# npcx4m8f register map
Registers are 8-bit, read-write, no defined reset value unless marked. A register's access mark holds for its fields unless they carry their own. Offsets are from the block's base; [hi:lo] are bit positions; {n}, {i} and the like mark numbered series.

## FIU — Flash Interface Unit
Base 0x40020000
0x00 FIU_CFG
  [7:0] FL_SIZE
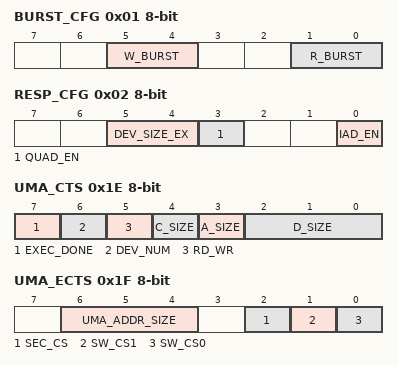
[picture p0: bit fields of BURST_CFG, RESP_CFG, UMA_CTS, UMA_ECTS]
0x01 BURST_CFG
  [5:4] W_BURST, [1:0] R_BURST
0x02 RESP_CFG
  [5:4] DEV_SIZE_EX, [3] QUAD_EN, [0] IAD_EN
0x14 SPI_FL_CFG
  [5:0] DEV_SIZE
0x16 UMA_CODE
{0x17+i} UMA_AB{i} (i=0..2)
{0x1A+i} UMA_DB{i} (i=0..3)
0x1E UMA_CTS
  [7] EXEC_DONE, [6] DEV_NUM, [5] RD_WR, [4] C_SIZE, [3] A_SIZE, [2:0] D_SIZE
0x1F UMA_ECTS
  [6:4] UMA_ADDR_SIZE, [2] SEC_CS, [1] SW_CS1, [0] SW_CS0
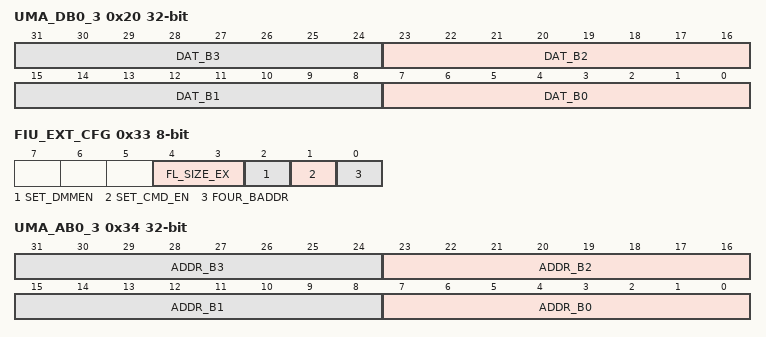
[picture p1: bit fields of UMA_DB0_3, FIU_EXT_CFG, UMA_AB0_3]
0x20 UMA_DB0_3 32-bit
  [8n+7:8n] DAT_B{n} (n=0..3)
0x30 UMA_RD_CMD
0x32 FIU_DMM_CYC
0x33 FIU_EXT_CFG
  [4:3] FL_SIZE_EX, [2] SET_DMMEN, [1] SET_CMD_EN, [0] FOUR_BADDR
0x34 UMA_AB0_3 32-bit
  [8n+7:8n] ADDR_B{n} (n=0..3)

## KBS — Keyboard Scan Module
Base 0x400A3000
0x04 KBSIN
0x05 KBSINPU
0x06 KBSOUT0 16-bit
0x08 KBSOUT1 16-bit
0x0A KBS_BUF_INDX
0x0B KBS_BUF_DATA
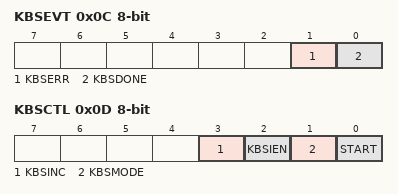
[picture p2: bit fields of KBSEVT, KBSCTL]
0x0C KBSEVT
  [1] KBSERR, [0] KBSDONE
0x0D KBSCTL
  [3] KBSINC, [2] KBSIEN, [1] KBSMODE, [0] START

## HFCG — High-Frequency Clock Generator
Base 0x400B5000
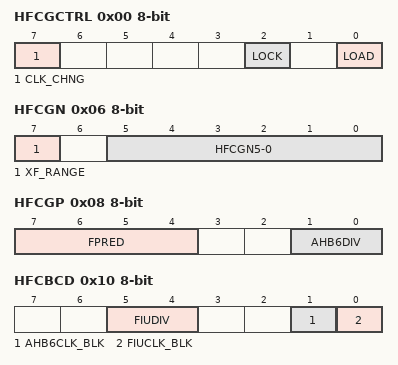
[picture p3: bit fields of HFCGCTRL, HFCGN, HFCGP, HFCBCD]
0x00 HFCGCTRL
  [7] CLK_CHNG, [2] LOCK, [0] LOAD
0x02 HFCGML
  [7:0] HFCGM7-0
0x04 HFCGMH
  [7:0] HFCGM15-8
0x06 HFCGN
  [7] XF_RANGE, [5:0] HFCGN5-0
0x08 HFCGP
  [7:4] FPRED, [1:0] AHB6DIV
0x0A HFCG_VER
  [3:0] HFCG_VER
0x10 HFCBCD
  [5:4] FIUDIV, [1] AHB6CLK_BLK, [0] FIUCLK_BLK
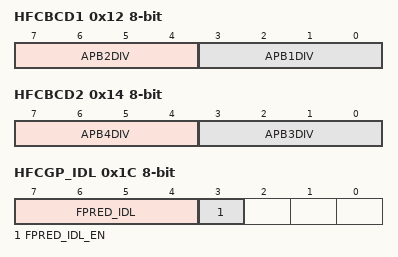
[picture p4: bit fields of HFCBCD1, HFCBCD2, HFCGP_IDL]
0x12 HFCBCD1
  [7:4] APB2DIV, [3:0] APB1DIV
0x14 HFCBCD2
  [7:4] APB4DIV, [3:0] APB3DIV
0x1C HFCGP_IDL
  [7:4] FPRED_IDL, [3] FPRED_IDL_EN

## LFCG — Low-Frequency Clock Generator
Base 0x400B5100
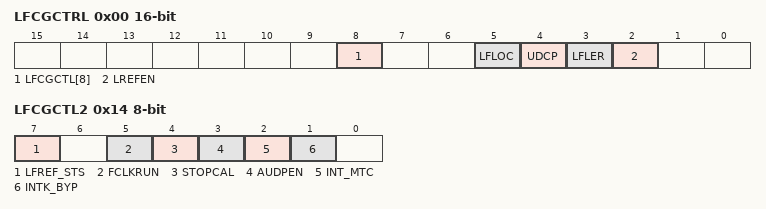
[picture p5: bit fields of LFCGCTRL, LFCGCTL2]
0x00 LFCGCTRL 16-bit
  [8] LFCGCTL[8], [5] LFLOC, [4] UDCP, [3] LFLER, [2] LREFEN
0x02 HFRDI 16-bit
  [11:0] HFRDI11-0
0x04 HFRDF 16-bit
  [15:0] HFRDF15-0
0x06 FRCDIV 16-bit
  [8:0] FRCDIV8-0
0x08 DIVMIN 16-bit
  [8:0] DIVMIN8-0
0x0A DIVMAX 16-bit
  [8:0] DIVMAX8-0
0x0E LFCG_VER
0x14 LFCGCTL2
  [7] LFREF_STS, [5] FCLKRUN, [4] STOPCAL, [3] AUDPEN, [2] INT_MTC, [1] INTK_BYP

## CR_UART0 — Core UART
Base 0x400E0000
Same registers: CR_UART1 0x400E2000, CR_UART2 0x400E4000, CR_UART3 0x400E6000
0x00 UTBUF
0x02 URBUF
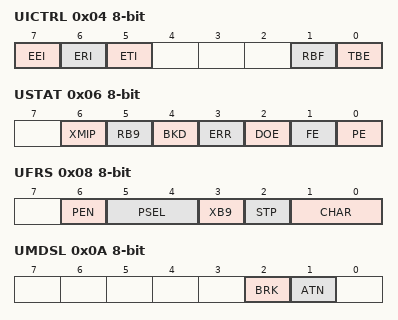
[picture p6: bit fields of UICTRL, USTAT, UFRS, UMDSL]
0x04 UICTRL
  [7] EEI, [6] ERI, [5] ETI, [1] RBF, [0] TBE
0x06 USTAT
  [6] XMIP, [5] RB9, [4] BKD, [3] ERR, [2] DOE, [1] FE, [0] PE
0x08 UFRS
  [6] PEN, [5:4] PSEL, [3] XB9, [2] STP, [1:0] CHAR
0x0A UMDSL
  [2] BRK, [1] ATN
0x0C UBAUD
  [7:0] UDIV7-0
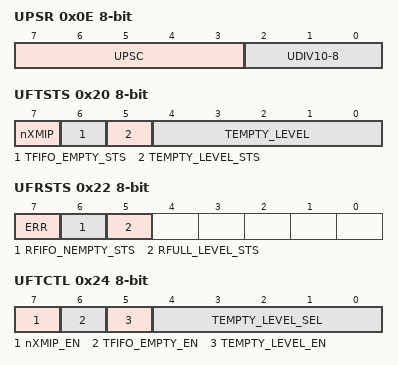
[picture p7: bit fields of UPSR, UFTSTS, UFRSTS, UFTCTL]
0x0E UPSR
  [7:3] UPSC, [2:0] UDIV10-8
0x20 UFTSTS
  [7] nXMIP, [6] TFIFO_EMPTY_STS, [5] TEMPTY_LEVEL_STS, [4:0] TEMPTY_LEVEL
0x22 UFRSTS
  [7] ERR, [6] RFIFO_NEMPTY_STS, [5] RFULL_LEVEL_STS
0x24 UFTCTL
  [7] nXMIP_EN, [6] TFIFO_EMPTY_EN, [5] TEMPTY_LEVEL_EN, [4:0] TEMPTY_LEVEL_SEL
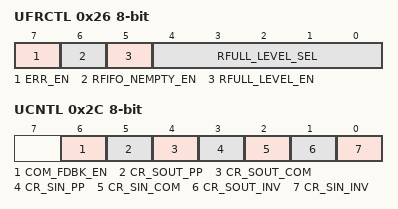
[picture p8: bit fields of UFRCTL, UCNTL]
0x26 UFRCTL
  [7] ERR_EN, [6] RFIFO_NEMPTY_EN, [5] RFULL_LEVEL_EN, [4:0] RFULL_LEVEL_SEL
0x2C UCNTL
  [6] COM_FDBK_EN, [5] CR_SOUT_PP, [4] CR_SOUT_COM, [3] CR_SIN_PP, [2] CR_SIN_COM, [1] CR_SOUT_INV, [0] CR_SIN_INV

## PECI — PECI Controller
Base 0x400D4000
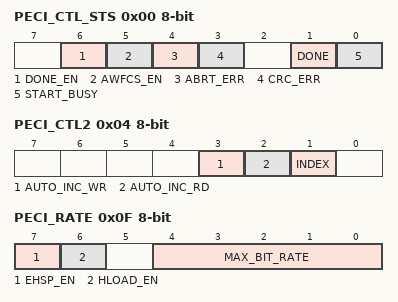
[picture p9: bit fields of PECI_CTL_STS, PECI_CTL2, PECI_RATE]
0x00 PECI_CTL_STS
  [6] DONE_EN, [5] AWFCS_EN, [4] ABRT_ERR, [3] CRC_ERR, [1] DONE, [0] START_BUSY
0x01 PECI_RD_LENGTH
0x02 PECI_ADDR
0x03 PECI_CMD
0x04 PECI_CTL2
  [3] AUTO_INC_WR, [2] AUTO_INC_RD, [1] INDEX
0x05 PECI_INDEX
0x06 PECI_IDATA
0x07 PECI_WR_LENGTH
0x0B PECI_WR_FCS
0x0C PECI_RD_FCS
0x0D PECI_AW_FCS
0x0F PECI_RATE
  [7] EHSP_EN, [6] HLOAD_EN, [4:0] MAX_BIT_RATE
{0x10+i} PECI_DATA_IN{i} (i=0..9)
0x1A PECI_DATA_INA
0x1B PECI_DATA_INB
0x1C PECI_DATA_INC
0x1D PECI_DATA_IND
0x1E PECI_DATA_INE
0x1F PECI_DATA_INF
{0x20+i} PECI_DATA_OUT{i} (i=0..9)
0x2A PECI_DATA_OUTA
0x2B PECI_DATA_OUTB
0x2C PECI_DATA_OUTC
0x2D PECI_DATA_OUTD
0x2E PECI_DATA_OUTE
0x2F PECI_DATA_OUTF

## GPIO0 — GENERAL-PURPOSE I/O
Base 0x40081000
0x00 P0DOUT
0x01 P0DIN
0x02 P0DIR
0x03 P0PULL
0x04 P0PUD
0x05 P0ENVDD
0x06 P0OTYPE

## GPIO1 — GENERAL-PURPOSE I/O
Base 0x40083000
0x00 P1DOUT
0x01 P1DIN
0x02 P1DIR
0x03 P1PULL
0x04 P1PUD
0x05 P1ENVDD
0x06 P1OTYPE
